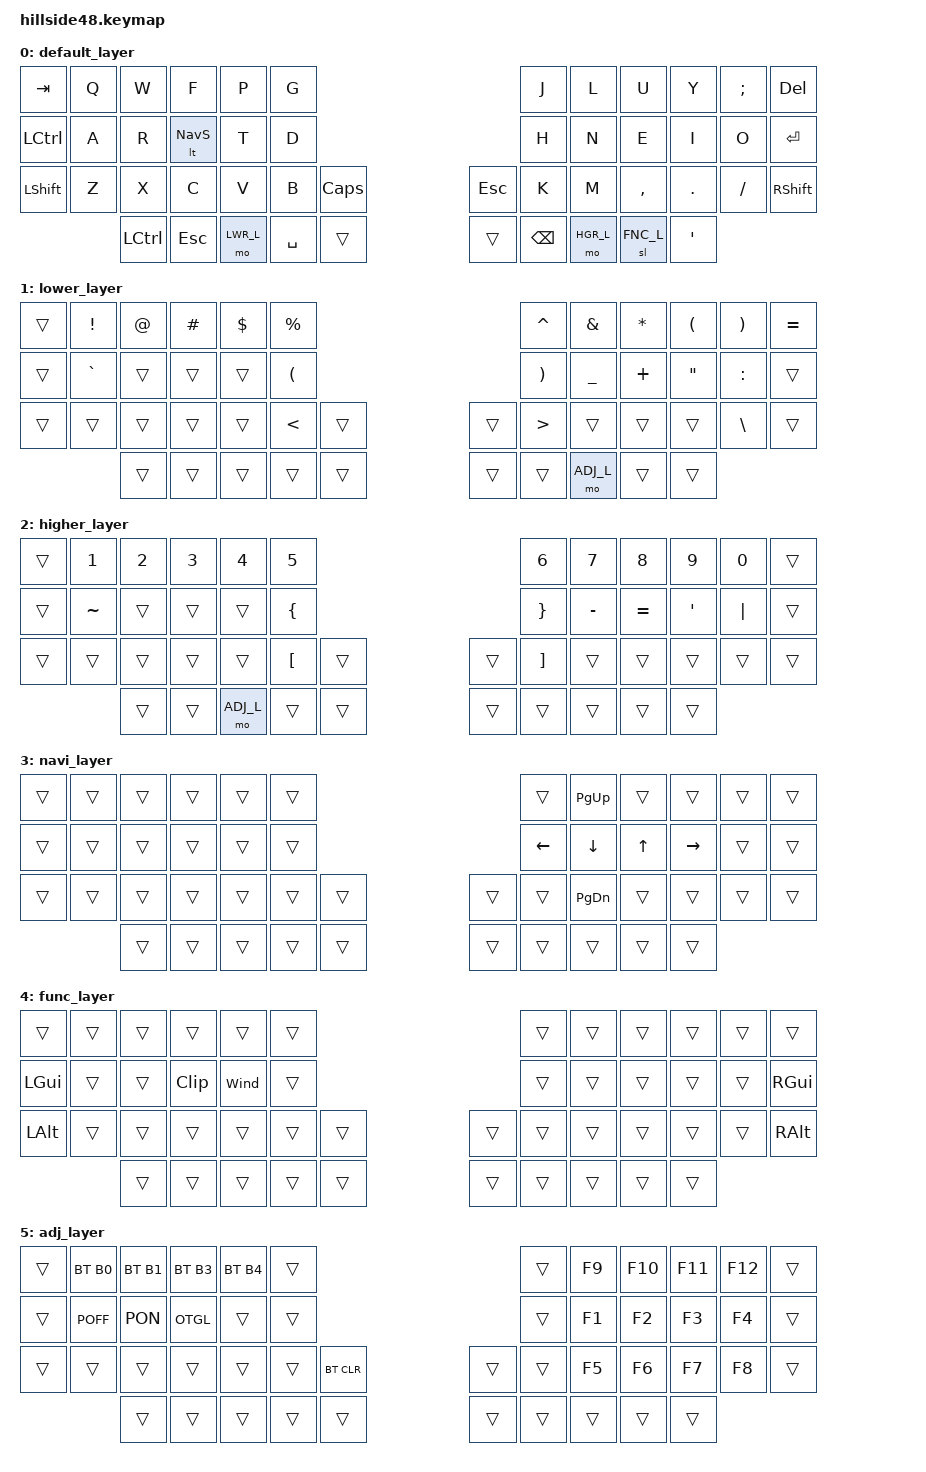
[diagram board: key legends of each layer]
/*
 * Copyright (c) 2022 The ZMK Contributors
 *
 * SPDX-License-Identifier: MIT
 */

#include <behaviors.dtsi>
#include <dt-bindings/zmk/bt.h>
#include <dt-bindings/zmk/ext_power.h>
#include <dt-bindings/zmk/keys.h>
#include <dt-bindings/zmk/outputs.h>

#define COLEMK_L 0
#define LWR_L    1
#define HGR_L    2
#define NAV_L    3
#define FNC_L    4
#define ADJ_L    5

#define Undo   LC(Z)
#define Cut    LC(X)
#define Copy   LC(C)
#define Paste  LC(V)
#define Clip   LG(LS(S))
#define Wind   LA(PSCRN)
#define NavS   NAV_L S
#define B0     BT_SEL 0
#define B1     BT_SEL 1
#define B2     BT_SEL 2
#define B3     BT_SEL 3
#define B4     BT_SEL 4
#define POFF   ext_power EP_OFF 
#define PON    ext_power EP_ON
#define OTGL   out OUT_TOG

&mt {
	flavor = "tap-preferred";
        tapping_term_ms = <185>;
        retro-tap;
};

&lt {
	flavor = "tap-preferred";
        tapping_term_ms = <185>;
	retro-tap;
};

&sl {
        release-after-ms = <2000>;
};

/ {
        keymap {
                compatible = "zmk,keymap";

                default_layer {
                        bindings = <
&kp TAB    &kp Q  &kp W      &kp F     &kp P    &kp G                                                      &kp J      &kp L     &kp U      &kp Y    &kp SEMI   &kp DEL
&kp LCTRL  &kp A  &kp R      &lt NavS  &kp T    &kp D                                                      &kp H      &kp N     &kp E      &kp I    &kp O      &kp ENTER
&kp LSHFT  &kp Z  &kp X      &kp C     &kp V    &kp B      &kp CAPS                              &kp ESC   &kp K      &kp M     &kp COMMA  &kp DOT  &kp SLASH  &kp RSHFT
                  &kp LCTRL            &kp ESC  &mo LWR_L  &kp SPACE  &trans             &trans  &kp BSPC  &mo HGR_L  &sl FNC_L            &kp SQT   
                        >;
			
                        sensor-bindings = <&inc_dec_kp C_VOL_UP C_VOL_DN &inc_dec_kp PG_UP PG_DN>;
                };

                lower_layer {
                        bindings = <
&trans  &kp EXCL   &kp AT  &kp HASH  &kp DLLR  &kp PRCNT                                             &kp CARET  &kp AMPS   &kp STAR  &kp LPAR  &kp RPAR   &kp EQUAL
&trans  &kp GRAVE  &trans  &trans    &trans    &kp LPAR                                              &kp RPAR   &kp UNDER  &kp PLUS  &kp DQT   &kp COLON  &trans
&trans  &trans     &trans  &trans    &trans    &kp LT     &trans                             &trans  &kp GT     &trans     &trans    &trans    &kp BSLH   &trans
                   &trans            &trans    &trans     &trans  &trans             &trans  &trans  &mo ADJ_L  &trans               &trans   
                        >;
			
                        sensor-bindings = <&inc_dec_kp C_VOL_UP C_VOL_DN &inc_dec_kp PG_UP PG_DN>;
                };

                higher_layer {
                        bindings = <
&trans  &kp N1     &kp N2  &kp N3  &kp N4  &kp N5                                                &kp N6    &kp N7     &kp N8     &kp N9   &kp N0   &trans
&trans  &kp TILDE  &trans  &trans  &trans  &kp LBRC                                              &kp RBRC  &kp MINUS  &kp EQUAL  &kp SQT  &kp PIPE  &trans
&trans  &trans     &trans  &trans  &trans  &kp LBKT   &trans                             &trans  &kp RBKT  &trans     &trans     &trans   &trans  &trans
                   &trans          &trans  &mo ADJ_L  &trans  &trans             &trans  &trans  &trans    &trans                &trans   
                        >;
			
                        sensor-bindings = <&inc_dec_kp C_VOL_UP C_VOL_DN &inc_dec_kp PG_UP PG_DN>;
                };

                navi_layer {
                        bindings = <
&trans  &trans  &trans  &trans  &trans  &trans                                             &trans    &kp PG_UP  &trans  &trans     &trans  &trans
&trans  &trans  &trans  &trans  &trans  &trans                                             &kp LEFT  &kp DOWN   &kp UP  &kp RIGHT  &trans  &trans
&trans  &trans  &trans  &trans  &trans  &trans  &trans                             &trans  &trans    &kp PG_DN  &trans  &trans     &trans  &trans
                &trans          &trans  &trans  &trans  &trans             &trans  &trans  &trans    &trans             &trans   
                        >;
			
                        sensor-bindings = <&inc_dec_kp C_VOL_UP C_VOL_DN &inc_dec_kp PG_UP PG_DN>;
                };

                func_layer {
                        bindings = <
&trans    &trans  &trans  &trans    &trans    &trans                                           &trans  &trans  &trans  &trans  &trans  &trans
&kp LGUI  &trans  &trans  &kp Clip  &kp Wind  &trans                                           &trans  &trans  &trans  &trans  &trans  &kp RGUI
&kp LALT  &trans  &trans  &trans    &trans  &trans  &trans                             &trans  &trans  &trans  &trans  &trans  &trans  &kp RALT
                  &trans            &trans  &trans  &trans  &trans             &trans  &trans  &trans  &trans          &trans   
                        >;
			
                        sensor-bindings = <&inc_dec_kp C_VOL_UP C_VOL_DN &inc_dec_kp PG_UP PG_DN>;
                };

                adj_layer {
                        bindings = <
&trans  &bt B0  &bt B1  &bt B3  &bt B4  &trans                                             &trans  &kp F9  &kp F10  &kp F11  &kp F12  &trans
&trans  &POFF   &PON    &OTGL   &trans  &trans                                             &trans  &kp F1  &kp F2   &kp F3   &kp F4   &trans
&trans  &trans  &trans  &trans  &trans  &trans  &bt BT_CLR                         &trans  &trans  &kp F5  &kp F6   &kp F7   &kp F8   &trans
                &trans          &trans  &trans  &trans      &trans         &trans  &trans  &trans  &trans             &trans   
                        >;
			
                        sensor-bindings = <&inc_dec_kp C_VOL_UP C_VOL_DN &inc_dec_kp PG_UP PG_DN>;
                };
        };
};
